# 3065ARPIRZ register map
File version: 1.0
Registers are 32-bit, access per field, reset 0x0 unless marked. A register's access mark holds for its fields unless they carry their own. Offsets are from the block's base; [hi:lo] are bit positions; {n}, {i} and the like mark numbered series.

## ADC0 — ADC peripheral interface
Base 0x18000000
Same registers: ADC1 0x18001000, ADC2 0x18002000
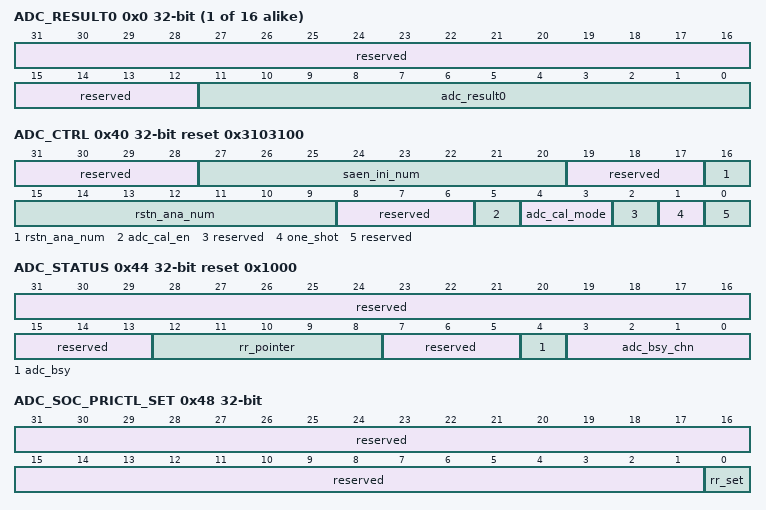
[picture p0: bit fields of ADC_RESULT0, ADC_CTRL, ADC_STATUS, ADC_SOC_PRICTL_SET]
{0x0+4i} ADC_RESULT{i} ro (i=0..15) — ADC结果寄存器{i}。
  [31:12] reserved — 保留。
  [11:0] adc_result{i} — SOC{i}结果寄存器。
0x40 ADC_CTRL reset 0x3103100 — ADC控制寄存器。
  [31:28] reserved ro — 保留。
  [27:20] saen_ini_num rw — 模拟的SAEN信号在adc_pwdnz拉高后需要持续为高的时间。按照clk_adc进行计数。默认计数值49，对应持续49+1个clk_adc的时钟周期，clk_adc=40M时则表示SAEN持续1250ns。该寄存器需要在ADC_ANA_PD[adc_pwdnz]配置为1之前进行配置。且该寄存器的配置值需要大于rstn_ana_num。
  [19:17] reserved ro — 保留。
  [16:9] rstn_ana_num rw — 模拟使能ADC_ANA_PD[adc_pwdnz]后，在拉起模拟复位的延迟计数值，按照clk_adc进行计数。默认计数值24，对应clk_adc=40M时的625ns。 延迟计算：rstn_ana_num*T(clk_adc)； 例：rstn_ana_num=24，clk_adc=40M。则对应延迟(24+1)*1/40M=625ns 需要保证延迟值至少大于400ns。
  [8:6] reserved ro — 保留。
  [5] adc_cal_en rw — ADC校准使能。 0: 不校准。 1: 根据校准模式。
  [4:3] adc_cal_mode rw — 校准模式选择。 adc_cal_en = 0时： 0：正常工作状态； 其他：保留。 adc_cal_en=1时： 0：offset校准； 1：电容校准； 其他：保留。
  [2] reserved ro — 保留。
  [1] one_shot rw — 阻塞轮询模式使能。 0：不使能。 1：使能。
  [0] reserved ro — 保留。
0x44 ADC_STATUS ro reset 0x1000 — ADC工作状态寄存器。
  [31:13] reserved — 保留。
  [12:8] rr_pointer — 轮询指针。该指针保持上一个转换完的轮询SOC，用于决定接下来的轮询SOC。 0：SOC0为上一个转换的轮询SOC，SOC1有最高优先级。 1：SOC1为上一个转换的轮询SOC，SOC2有最高优先级。 … 15：SOC15为上一个转换的轮询SOC，SOC0有最高优先级。 16：轮询指针复位、或写轮询指针时置为该值，SOC0有最高优先级。在写轮询指针时，若当前正在转换，则等转换结束后生效。
  [7:5] reserved — 保留。
  [4] adc_bsy — 对应输出的 adc_adst。 ADC 状态寄存器，在有 soc_flg 拉高时置1，在所有SOC均转换结束后置 0。 0： ADC 允许下一次转换； 1： ADC 正在进行一次转换。
  [3:0] adc_bsy_chn — ADC繁忙通道，adc_bsy=1时，指向当前转换的SOC，当adc_bsy=0时，保持之前转换的SOC。 0x0：SOC0正在转换，或为上一个转换的通道； 0x1：SOC1正在转换，或为上一个转换的通道； … 0xF：SOC15正在转换，或为上一个转换的通道。
0x48 ADC_SOC_PRICTL_SET — ADC轮询指针置位。
  [31:1] reserved ro — 保留。
  [0] rr_set rw write-1-clears — 轮询指针软件复位，软件置1后，ADC_STATUS[rr_pointer]置为16。表示SOC0优先级最高。
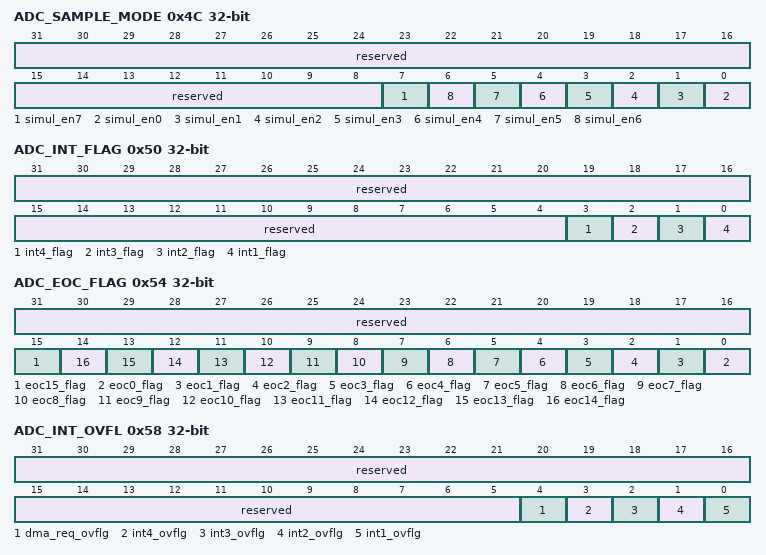
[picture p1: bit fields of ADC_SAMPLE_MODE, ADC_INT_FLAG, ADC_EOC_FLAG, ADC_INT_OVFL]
0x4C ADC_SAMPLE_MODE — ADC采样模式控制。
  [31:8] reserved ro — 保留。
  [7] simul_en7 rw — SOC15，SOC14的采样模式选择。 0：SOC15，SOC14独立，各自完成采样。 1：SOC15，SOC14为同步采样模式。在触发后，SOC14和SOC15同时完成采样/保持，然后SOC14先转换并将转换结果至于adc_result14，SOC15后转换并将转换结果至于adc_result15。
  [n] simul_en{n} rw (n=0..6) — SOC{2n+1},SOC{2n}的采样模式选择。
0x50 ADC_INT_FLAG — ADC中断状态寄存器。
  [31:4] reserved ro — 保留。
  [3] int4_flag rw write-1-clears — ADC中断寄存器4，写1清。 0：没有中断产生； 1：中断寄存器4存在中断产生。 在连续转换模式下，中断将以脉冲形式送出，并且即使中断寄存器4中存在未清除的中断，仍可产生新的中断。 在非连续模式下，在每次转换结束后产生中断，将中断寄存器4置为1，保持到软件清除中断。在软件清除中断前不会出现新的中断。
  [2] int3_flag rw write-1-clears — ADC中断寄存器3。
  [1] int2_flag rw write-1-clears — ADC中断寄存器2。
  [0] int1_flag rw write-1-clears — ADC中断寄存器1。
0x54 ADC_EOC_FLAG — ADC eoc状态寄存器。
  [31:16] reserved ro — 保留。
  [15] eoc15_flag rw write-1-clears — ADC eoc15状态寄存器，写1清。 0：自上次清除后，没有eoc产生； 1：自上次清除后，存在eoc产生。
  [n] eoc{n}_flag rw write-1-clears (n=0..14) — ADC eoc{n}寄存器。
0x58 ADC_INT_OVFL — ADC中断溢出寄存器。
  [31:5] reserved ro — 保留。
  [4] dma_req_ovflg rw write-1-clears — dma请求溢出标志，写1清。
  [3] int4_ovflg rw write-1-clears — ADC中断溢出寄存器4，写1清。 0：没有中断溢出产生； 1：中断寄存器4存在中断溢出产生。 若在未清除中断时，再出现新的中断，则会产生中断溢出。
  [2] int3_ovflg rw write-1-clears — ADC中断溢出寄存器3。
  [1] int2_ovflg rw write-1-clears — ADC中断溢出寄存器2。
  [0] int1_ovflg rw write-1-clears — ADC中断溢出寄存器1。
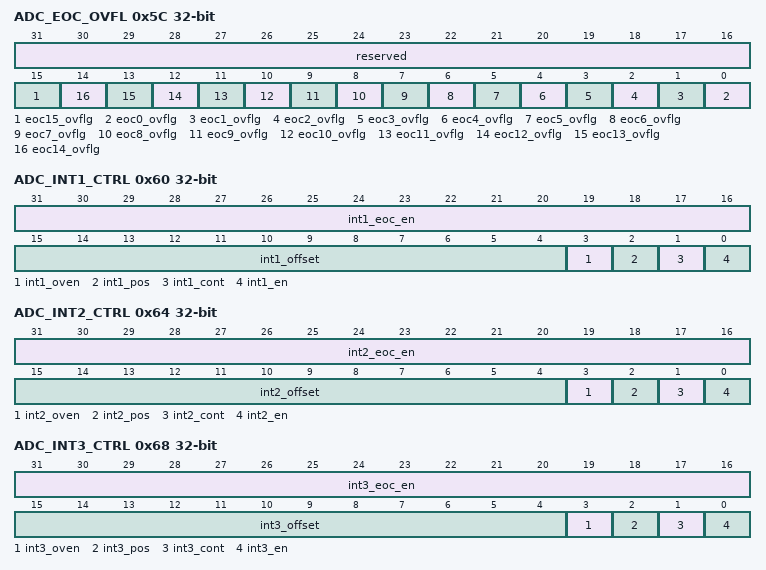
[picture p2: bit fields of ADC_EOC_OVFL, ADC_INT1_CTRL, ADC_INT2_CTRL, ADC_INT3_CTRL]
0x5C ADC_EOC_OVFL — ADC eoc溢出寄存器。
  [31:16] reserved ro — 保留。
  [15] eoc15_ovflg rw write-1-clears — ADC eoc15溢出状态寄存器，写1清。 0：自上次清除后，没有eoc溢出； 1：自上次清除后，存在eoc溢出。
  [n] eoc{n}_ovflg rw write-1-clears (n=0..14) — ADC eoc{n}溢出寄存器。
0x60 ADC_INT1_CTRL rw — ADC中断1控制寄存器。
  [31:16] int1_eoc_en — 可以触发中断1的eoc使能。 对应bit为0：该eoc不能触发中断1； 对应bit为1：该eoc可以触发中断1。
  [15:4] int1_offset — int1_pos为0时，不论int1_offset为何值，均在转换结束时产生中断； int1_pos为1时，在采样/保持信号下降沿偏移int1_offset后产生中断； 当int1_offset大于采样/保持信号下降沿到转换结束的延迟时，中断应在转换结束时产生。
  [3] int1_oven — 中断1的溢出标志的使能。 0：中断1不产生溢出； 1：中断1会产生溢出。
  [2] int1_pos — 提前中断模式。 0：不使能； 1：使能。 一次采样包括采样和转换两个过程，提前中断表示，在采样结束偏移。int1_offset值后，产生中断；正常中断则在转换结束后产生中断。
  [1] int1_cont — 中断1脉冲使能。 0：表示输出为电平中断； 1：表示输出为脉冲中断。
  [0] int1_en — 中断1使能。 0：不使能； 1：使能。
0x64 ADC_INT2_CTRL rw — ADC中断2控制寄存器。
  [31:16] int2_eoc_en — 可以触发中断2的eoc使能。 同ADC_INT1_CTRL描述。
  [15:4] int2_offset — 中断2提前中断偏移值。 同ADC_INT1_CTRL描述。
  [3] int2_oven — 中断2的溢出标志的使能。 同ADC_INT1_CTRL描述。
  [2] int2_pos — 提前中断模式。 同ADC_INT1_CTRL描述。
  [1] int2_cont — 中断2脉冲使能。 同ADC_INT1_CTRL描述。
  [0] int2_en — 中断2使能。 同ADC_INT1_CTRL描述。
0x68 ADC_INT3_CTRL rw — ADC中断3控制寄存器。
  [31:16] int3_eoc_en — 可以触发中断3的eoc使能 。 同ADC_INT1_CTRL描述。
  [15:4] int3_offset — 中断3提前中断偏移值。 同ADC_INT1_CTRL描述。
  [3] int3_oven — 中断3的溢出标志的使能。 同ADC_INT1_CTRL描述。
  [2] int3_pos — 提前中断模式。 同ADC_INT1_CTRL描述。
  [1] int3_cont — 中断3脉冲使能。 同ADC_INT1_CTRL描述。
  [0] int3_en — 中断3使能。 同ADC_INT1_CTRL描述。
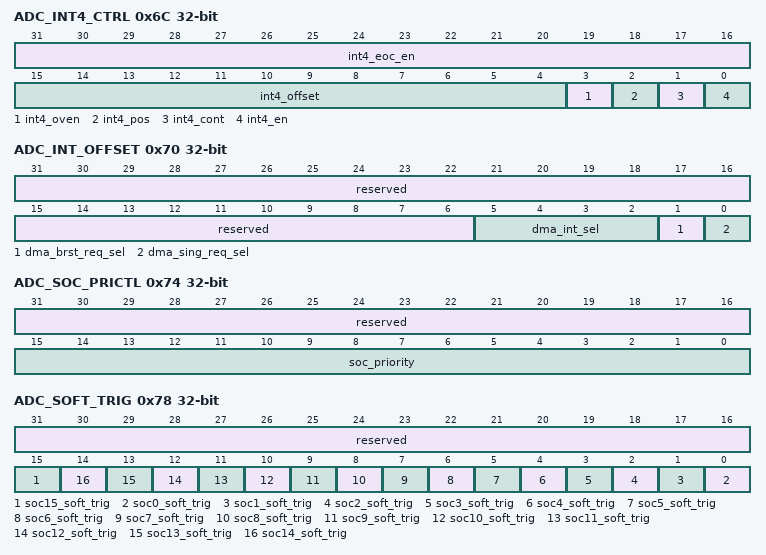
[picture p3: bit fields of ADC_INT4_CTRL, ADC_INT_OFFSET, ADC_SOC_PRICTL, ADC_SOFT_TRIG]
0x6C ADC_INT4_CTRL rw — ADC中断4控制寄存器。
  [31:16] int4_eoc_en — 可以触发中断4的eoc使能 。 同ADC_INT1_CTRL描述。
  [15:4] int4_offset — 中断4提前中断偏移值。 同ADC_INT1_CTRL描述。
  [3] int4_oven — 中断4的溢出标志的使能。 同ADC_INT1_CTRL描述。
  [2] int4_pos — 提前中断模式。 同ADC_INT1_CTRL描述。
  [1] int4_cont — 中断4脉冲使能。 同ADC_INT1_CTRL描述。
  [0] int4_en — 中断4使能。 同ADC_INT1_CTRL描述。
0x70 ADC_INT_OFFSET — ADC DMA请求寄存器。
  [31:6] reserved ro — 保留。
  [5:2] dma_int_sel rw — DMA中断源选择。 0x0：eoc0； 0x1：eoc1； ... 0xF：eoc15。
  [1] dma_brst_req_sel rw — DMA BURST请求使能。 0：不使能； 1：使能。
  [0] dma_sing_req_sel rw — DMA SINGLE请求使能。 0：不使能； 1：使能。
0x74 ADC_SOC_PRICTL — ADC优先级控制。
  [31:16] reserved ro — 保留。
  [15:0] soc_priority rw — 高优先级配置值，优先级配置只能有如下16种配置方法，其他方法非法。 0x0000：所有SOC均为轮询SOC； 0x0001：SOC0有高优先级，SOC1-SOC15为轮询SOC； 0x0003：SOC0、SOC1有高优先级，SOC2~SOC15为轮询SOC； … 0x7FFF：SOC0-SOC14有高优先级，SOC15为轮询SOC； 0xFFFF：所有SOC有高优先级； 其他：非法配置。
0x78 ADC_SOFT_TRIG — ADC软件触发。
  [31:16] reserved ro — 保留。
  [15] soc15_soft_trig rw write-1-clears — SOC15软件触发，读0。 0：无软件触发； 1：SOC15软件触发，脉冲形式。
  [n] soc{n}_soft_trig rw write-1-clears (n=0..14) — SOC{n}软件触发。
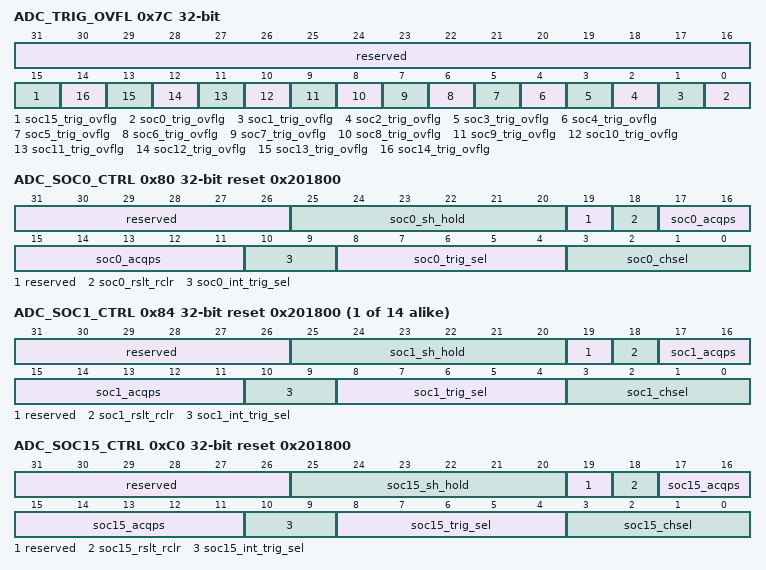
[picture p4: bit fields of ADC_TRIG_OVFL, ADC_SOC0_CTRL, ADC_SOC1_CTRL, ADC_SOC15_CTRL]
0x7C ADC_TRIG_OVFL — ADC触发溢出寄存器。
  [31:16] reserved ro — 保留。
  [15] soc15_trig_ovflg rw write-1-clears — SOC15触发溢出寄存器，写1清。 0：无触发溢出； 1：SOC15触发溢出。
  [n] soc{n}_trig_ovflg rw write-1-clears (n=0..14) — SOC{n}触发溢出寄存器。
0x80 ADC_SOC0_CTRL reset 0x201800 — ADC SOC0寄存器。
  [31:26] reserved ro — 保留。
  [25:20] soc0_sh_hold rw — SOC的电容充电后的保持时间长度，值范围2~28（其余值未定义）。配置为2则表示S/H电路持续保持2个clk_adc的时钟。
  [19] reserved ro — 保留。
  [18] soc0_rslt_rclr rw — SOC0结果寄存器，是否读清使能（可配合提前中断使用）。 0：读清不使能； 1：读清使能。
  [17:11] soc0_acqps rw — SOC0电容充电时间，范围3-127，对应时间：4-128个clk_adc。
  [10:9] soc0_int_trig_sel rw — SOC0反馈的中断触发配置。 00：不使用中断触发； 01：中断1触发SOC0； 10：中断2触发SOC0； 11：中断3触发SOC0。
  [8:4] soc0_trig_sel rw — SOC0触发器选择。 0x00：无接口上的触发，仅能通过软件触发。 0x01：trig_in_1（apt0_adca）； 0x02：trig_in_2（apt0_adcb）； 0x03：trig_in_3（apt1_adca）； 0x04：trig_in_4（apt1_adcb）； 0x05：trig_in_5（0apt2_adca）； 0x06：trig_in_6（0apt2_adcb）； 0x07：trig_in_7（apt3_adca）； 0x08：trig_in_8（apt3_adcb）； 0x09：trig_in_9（apt4_adca）； 0x0A：trig_in_10（apt4_adcb）； 0x0B：trig_in_11（apt5_adca）； 0x0C：trig_in_12（apt5_adcb）； 0x0D：trig_in_13（apt6_adca）； 0x0E：trig_in_14（apt6_adcb）； 0x0F：trig_in_15（apt7_adca）； 0x10：trig_in_16（apt7_adcb）； 0x11：trig_in_17（apt8_adca）； 0x12：trig_in_18（apt8_adcb）； 0x13：trig_in_19（timer0）； 0x14：trig_in_20（timer1）； 0x15：trig_in_21（timer2）； 0x16：trig_in_22（timer3）； 0x17：trig_in_23（GPIO）； 其他：非法。
  [3:0] soc0_chsel rw — SOC0通道选择（同步采样时，相邻两个SOC通道应配置到A/B两个通道组）。 0x0：选择模拟通道ADCINA0； 0x1：选择模拟通道ADCINA1； … 0x7：选择模拟通道ADCINA7； 0x8：选择模拟通道ADCINB0； 0x9：选择模拟通道ADCINB1； … 0xF：选择模拟通道ADCINB7。
{0x80+4i} ADC_SOC{i}_CTRL reset 0x201800 (i=1..14) — ADC SOC{i}寄存器。
  [31:26] reserved ro — 保留。
  [25:20] soc{i}_sh_hold rw — SOC{i}的电容充电后的保持时间长度，值范围2-28，（其余值未定义）。
  [19] reserved ro — 保留。
  [18] soc{i}_rslt_rclr rw — SOC{i}结果寄存器读清使能。
  [17:11] soc{i}_acqps rw — SOC{i}电容充电时间。
  [10:9] soc{i}_int_trig_sel rw — SOC{i}反馈的中断触发配置。
  [8:4] soc{i}_trig_sel rw — SOC{i}触发器选择。
  [3:0] soc{i}_chsel rw — SOC{i}通道选择。
0xC0 ADC_SOC15_CTRL reset 0x201800 — ADC SOC15寄存器。
  [31:26] reserved ro — 保留。
  [25:20] soc15_sh_hold rw — SOC15的电容充电后的保持时间长度，值范围2-28，（其余值未定义）。
  [19] reserved ro — 保留。
  [18] soc15_rslt_rclr rw — SOC15结果寄存器读清使能。
  [17:11] soc15_acqps rw — SOC15电容充电时间。
  [10:9] soc15_int_trig_sel rw — SOC15反馈的中断触发配置。
  [8:4] soc15_trig_sel rw — SOC15触发器选择。
  [3:0] soc15_chsel rw — SOC15通道选择。
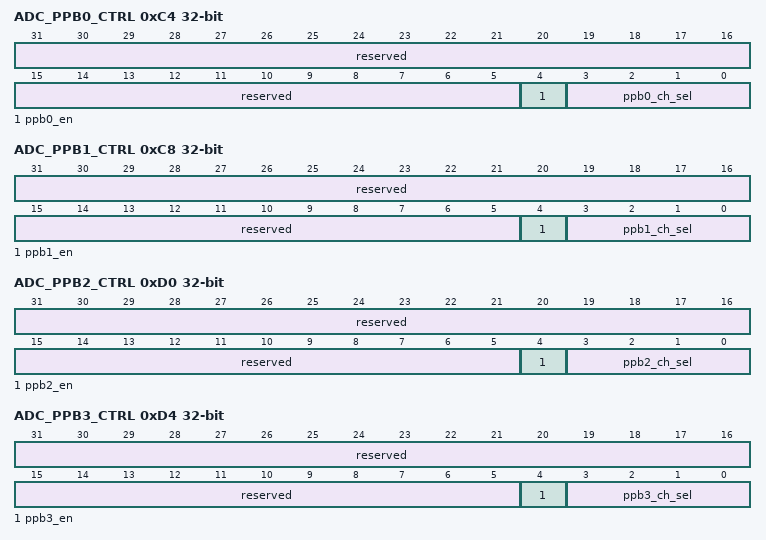
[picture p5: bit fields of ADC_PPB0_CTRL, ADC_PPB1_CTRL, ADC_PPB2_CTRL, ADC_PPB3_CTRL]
0xC4 ADC_PPB0_CTRL — ADC后处理模块0配置。
  [31:5] reserved ro — 保留。
  [4] ppb0_en rw — PPB0使能。 0：不使能； 1：使能PPB0。
  [3:0] ppb0_ch_sel rw — PPB0通道选择。 0x0：PPB0选择SOC0； 0x1：PPB0选择SOC1； … 0xF：PPB0选择SOC15。
0xC8 ADC_PPB1_CTRL — ADC后处理模块1配置。
  [31:5] reserved ro — 保留。
  [4] ppb1_en rw — PPB1使能。
  [3:0] ppb1_ch_sel rw — PPB1通道选择。
0xD0 ADC_PPB2_CTRL — ADC后处理模块2配置。
  [31:5] reserved ro — 保留。
  [4] ppb2_en rw — PPB2使能。
  [3:0] ppb2_ch_sel rw — PPB2通道选择。
0xD4 ADC_PPB3_CTRL — ADC后处理模块3配置。
  [31:5] reserved ro — 保留。
  [4] ppb3_en rw — PPB3使能。
  [3:0] ppb3_ch_sel rw — PPB3通道选择。
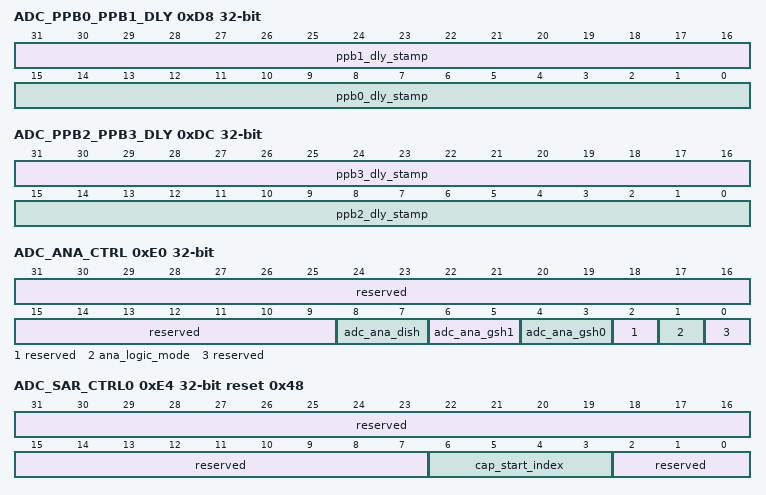
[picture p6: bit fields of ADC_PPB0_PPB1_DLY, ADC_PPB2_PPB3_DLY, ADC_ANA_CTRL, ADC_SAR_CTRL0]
0xD8 ADC_PPB0_PPB1_DLY ro — ADC后处理采样延迟。
  [31:16] ppb1_dly_stamp — 后处理模块1的采样延迟。 该延迟表示从对应soc_flg上升沿，到下降沿的计数值。
  [15:0] ppb0_dly_stamp — 后处理模块0的采样延迟。
0xDC ADC_PPB2_PPB3_DLY ro — ADC后处理采样延迟。
  [31:16] ppb3_dly_stamp — 后处理模块3的采样延迟。
  [15:0] ppb2_dly_stamp — 后处理模块2的采样延迟。
0xE0 ADC_ANA_CTRL — 模拟配置。
  [31:9] reserved ro — 保留。
  [8:7] adc_ana_dish rw — OFFSET校准控制。 00：不校准； 01：校准ADC CORE； 10：校准ADC CORE和SH电路； 11：保留。
  [6:5] adc_ana_gsh1 rw — S/H1衰减。 00：gain=1； 01：gain=0.75； 10：gain=0.6； 11：保留。
  [4:3] adc_ana_gsh0 rw — S/H0衰减。 00：gain=1； 01：gain=0.75； 10：gain=0.6； 11：保留。
  [2] reserved ro — 保留。
  [1] ana_logic_mode rw — ADC模拟工作模式。 0：正常工作模式； 1：电容校准模式。
  [0] reserved ro — 保留。
0xE4 ADC_SAR_CTRL0 reset 0x48 — SAR控制和电容校准控制寄存器。
  [31:7] reserved ro — 保留。
  [6:3] cap_start_index rw — 校准电容选择。
  [2:0] reserved ro — 保留。
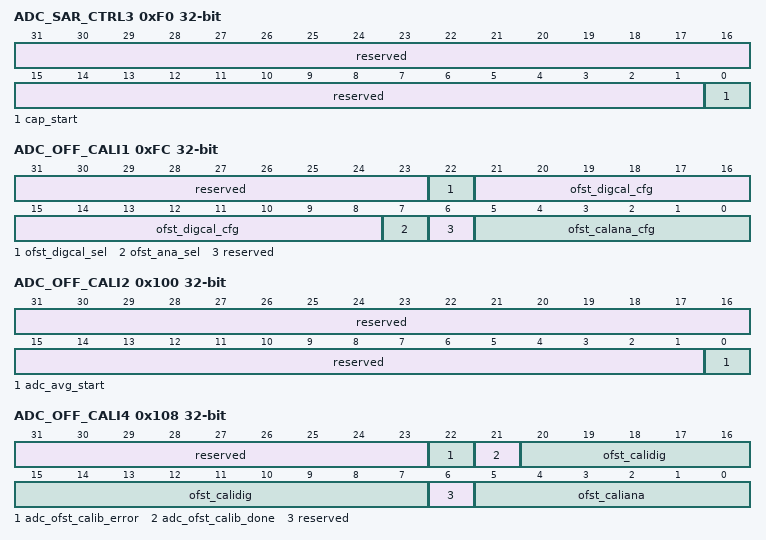
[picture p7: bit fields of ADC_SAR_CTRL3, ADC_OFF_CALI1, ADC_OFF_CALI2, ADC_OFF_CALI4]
0xF0 ADC_SAR_CTRL3 — SAR控制和电容校准控制寄存器。
  [31:1] reserved ro — 保留。
  [0] cap_start rw write-1-clears — 电容校准触发。
0xFC ADC_OFF_CALI1 — ADC offset校准。
  [31:23] reserved ro — 保留。
  [22] ofst_digcal_sel rw — 数字的offset输入源选择，不能与ofst_ana_sel同时配1。 0：软件配置值； 1：由逻辑自动产生的offset值。
  [21:8] ofst_digcal_cfg rw — fix(1,14,1)软件配置的数字offset。
  [7] ofst_ana_sel rw — 模拟的offset输入源选择，不能与ofst_digcal_sel同时配1。 0：软件配置值； 1：由逻辑自动产生的offset值。
  [6] reserved ro — 保留。
  [5:0] ofst_calana_cfg rw — 软件配置的模拟offset。 0x01：+0.5LSB； ... 0x1F：+15.5LSB； 0x3F：-0.5LSB； ... 0xA1：-15.5LSB； 默认：0x00。
0x100 ADC_OFF_CALI2 — ADC offset校准。
  [31:1] reserved ro — 保留。
  [0] adc_avg_start rw write-1-clears — 开始一次offset的均值计算。
0x108 ADC_OFF_CALI4 ro — ADC offset校准。
  [31:23] reserved — 保留。
  [22] adc_ofst_calib_error — offset校准错误标志。
  [21] adc_ofst_calib_done — offset校准结束标志。
  [20:7] ofst_calidig — fix(1, 14, 1)数字offset值。
  [6] reserved — 保留。
  [5:0] ofst_caliana — 模拟offset值。
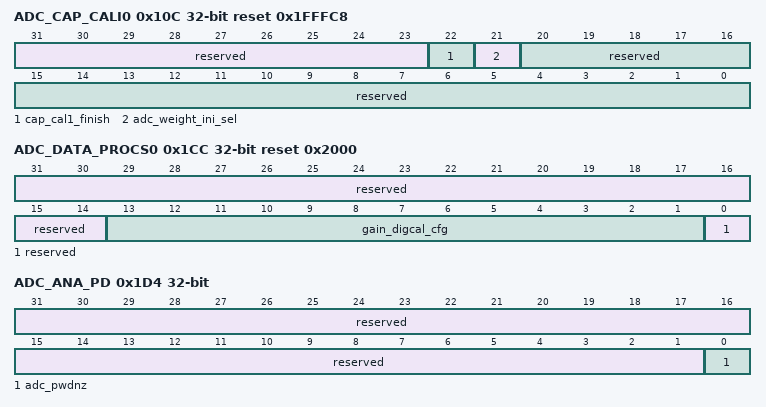
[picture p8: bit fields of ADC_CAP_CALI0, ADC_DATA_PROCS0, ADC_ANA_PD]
0x10C ADC_CAP_CALI0 reset 0x1FFFC8 — ADC电容校准寄存器。
  [31:23] reserved ro — 保留。
  [22] cap_cal1_finish ro — 电容校准完成标志。
  [21] adc_weight_ini_sel rw — 权重选择： 0：默认值； 1：逻辑校准值。
  [20:0] reserved ro — 保留。
0x1CC ADC_DATA_PROCS0 reset 0x2000 — ADC数据处理。
  [31:14] reserved ro — 保留。
  [13:1] gain_digcal_cfg rw — fix(0, 13, 12)软件配置校准增益数值。
  [0] reserved ro — 保留。
0x1D4 ADC_ANA_PD — ADC模拟电源使能。
  [31:1] reserved ro — 保留。
  [0] adc_pwdnz rw — ADC模拟电源。 0：关断； 1：使能。
